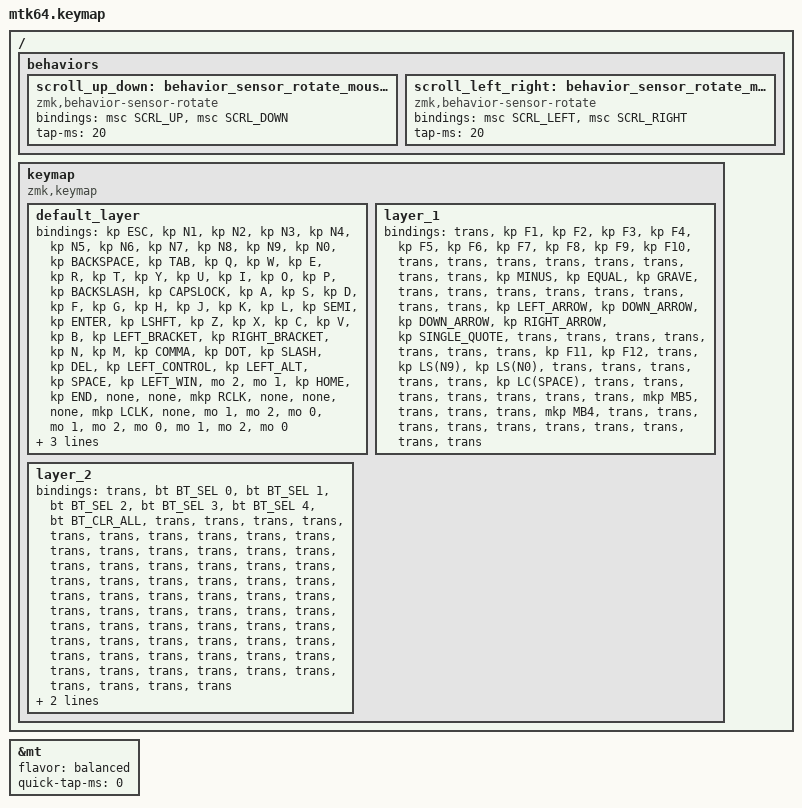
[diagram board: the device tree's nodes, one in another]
#include "keycode_japanese.h"
#include <behaviors.dtsi>
#include <dt-bindings/zmk/bt.h>
#include <dt-bindings/zmk/keys.h>
#include <dt-bindings/zmk/pointing.h>

// スクロール量の設定

#define ZMK_POINTING_DEFAULT_SCRL_VAL 100

&mt {
    flavor = "balanced";
    quick-tap-ms = <0>;
};

/ {
    behaviors {
        // 垂直スクロール用のbehaviorの設定

        scroll_up_down: behavior_sensor_rotate_mouse_wheel_up_down {
            compatible = "zmk,behavior-sensor-rotate";
            #sensor-binding-cells = <0>;
            bindings = <&msc SCRL_UP>, <&msc SCRL_DOWN>;

            tap-ms = <20>; // スクロールのタップ時間
        };

        // 水平スクロール用のbehaviorの設定

        scroll_left_right: behavior_sensor_rotate_mouse_wheel_left_right {
            compatible = "zmk,behavior-sensor-rotate";
            #sensor-binding-cells = <0>;
            bindings = <&msc SCRL_LEFT>, <&msc SCRL_RIGHT>;

            tap-ms = <20>; // スクロールのタップ時間
        };
    };
};

/ {
    keymap {
        compatible = "zmk,keymap";

        default_layer {
            bindings = <
&kp ESC  &kp N1  &kp N2  &kp N3  &kp N4  &kp N5  &kp N6  &kp N7  &kp N8  &kp N9  &kp N0  &kp BACKSPACE  &kp TAB  &kp Q  &kp W  &kp E  &kp R  &kp T  &kp Y  &kp U  &kp I  &kp O  &kp P  &kp BACKSLASH  &kp CAPSLOCK  &kp A  &kp S  &kp D  &kp F  &kp G  &kp H  &kp J  &kp K  &kp L  &kp SEMI  &kp ENTER  &kp LSHFT  &kp Z  &kp X  &kp C  &kp V  &kp B  &kp LEFT_BRACKET  &kp RIGHT_BRACKET  &kp N  &kp M  &kp COMMA  &kp DOT  &kp SLASH  &kp DEL  &kp LEFT_CONTROL  &kp LEFT_ALT  &kp SPACE  &kp LEFT_WIN  &mo 2  &mo 1  &kp HOME  &kp END  &none  &none  &mkp RCLK  &none  &none  &none  &mkp LCLK  &none  &mo 1  &mo 2  &mo 0  &mo 1  &mo 2  &mo 0  &mo 1  &mo 2  &mo 0
            >;

            sensor-bindings = <
                &inc_dec_kp LEFT_ARROW RIGHT_ARROW
                &inc_dec_kp UP_ARROW   DOWN_ARROW
            >;
        };

        layer_1 {
            bindings = <
&trans  &kp F1  &kp F2  &kp F3  &kp F4  &kp F5  &kp F6  &kp F7  &kp F8  &kp F9  &kp F10  &trans  &trans  &trans  &trans  &trans  &trans  &trans  &trans  &kp MINUS  &kp EQUAL  &kp GRAVE  &trans  &trans  &trans  &trans  &trans  &trans  &trans  &trans  &kp LEFT_ARROW  &kp DOWN_ARROW  &kp DOWN_ARROW  &kp RIGHT_ARROW  &kp SINGLE_QUOTE  &trans  &trans  &trans  &trans  &trans  &trans  &trans  &kp F11  &kp F12  &trans  &kp LS(N9)  &kp LS(N0)  &trans  &trans  &trans  &trans  &trans  &kp LC(SPACE)  &trans  &trans  &trans  &trans  &trans  &trans  &trans  &mkp MB5  &trans  &trans  &trans  &mkp MB4  &trans  &trans  &trans  &trans  &trans  &trans  &trans  &trans  &trans  &trans
            >;
        };

        layer_2 {
            bindings = <
&trans  &bt BT_SEL 0  &bt BT_SEL 1  &bt BT_SEL 2  &bt BT_SEL 3  &bt BT_SEL 4  &bt BT_CLR_ALL  &trans  &trans  &trans  &trans  &trans  &trans  &trans  &trans  &trans  &trans  &trans  &trans  &trans  &trans  &trans  &trans  &trans  &trans  &trans  &trans  &trans  &trans  &trans  &trans  &trans  &trans  &trans  &trans  &trans  &trans  &trans  &trans  &trans  &trans  &trans  &trans  &trans  &trans  &trans  &trans  &trans  &trans  &trans  &trans  &trans  &trans  &trans  &trans  &trans  &trans  &trans  &trans  &trans  &trans  &trans  &trans  &trans  &trans  &trans  &trans  &trans  &trans  &trans  &trans  &trans  &trans  &trans  &trans
            >;

            sensor-bindings = <
                &inc_dec_kp TAB LC(TAB) 
                &inc_dec_kp PG_UP PG_DN
            >;
        };
    };
};
